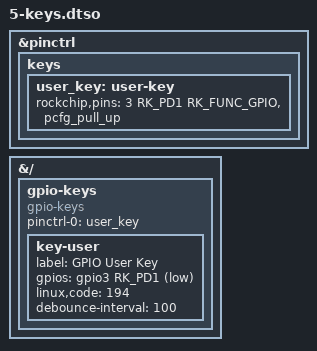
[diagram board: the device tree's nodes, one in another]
// SPDX-License-Identifier: (GPL-2.0+ OR MIT)
/dts-v1/; /plugin/;
#include <dt-bindings/gpio/gpio.h>
#include <dt-bindings/pinctrl/rockchip.h>
#include <dt-bindings/interrupt-controller/irq.h>
&pinctrl { keys { user_key: user-key { rockchip,pins = <3 RK_PD1 RK_FUNC_GPIO &pcfg_pull_up>; }; }; };
&{/} { gpio-keys { compatible = "gpio-keys"; pinctrl-names = "default"; pinctrl-0 = <&user_key>; key-user { label = "GPIO User Key"; gpios = <&gpio3 RK_PD1 GPIO_ACTIVE_LOW>; linux,code = <194>; debounce-interval = <100>; }; }; };
